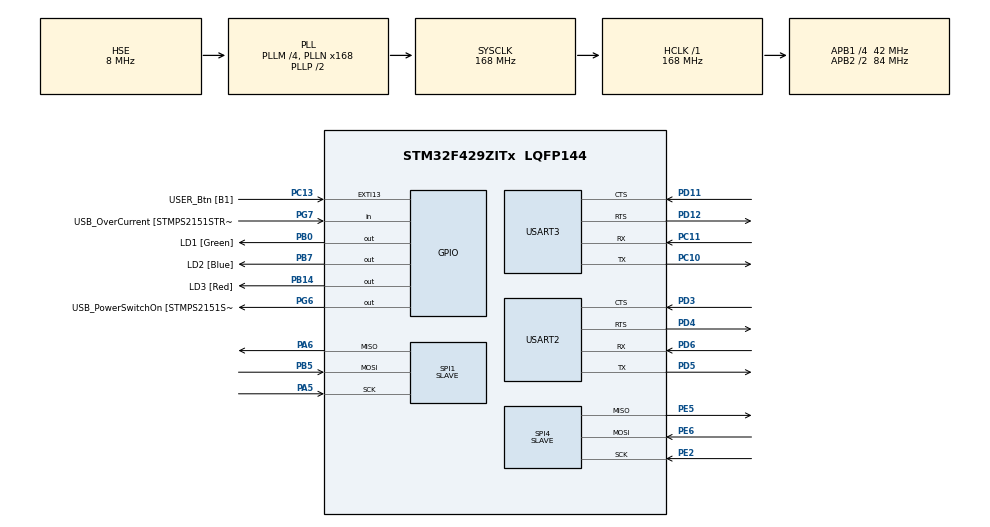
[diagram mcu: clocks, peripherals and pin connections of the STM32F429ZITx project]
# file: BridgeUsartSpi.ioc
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Dma.Request0=USART2_RX
Dma.Request1=SPI4_TX
Dma.Request2=SPI4_RX
Dma.Request3=USART2_TX
Dma.SPI4_RX.2.Direction=DMA_PERIPH_TO_MEMORY
Dma.SPI4_RX.2.FIFOMode=DMA_FIFOMODE_ENABLE
Dma.SPI4_RX.2.FIFOThreshold=DMA_FIFO_THRESHOLD_FULL
Dma.SPI4_RX.2.Instance=DMA2_Stream0
Dma.SPI4_RX.2.MemBurst=DMA_MBURST_SINGLE
Dma.SPI4_RX.2.MemDataAlignment=DMA_MDATAALIGN_BYTE
Dma.SPI4_RX.2.MemInc=DMA_MINC_ENABLE
Dma.SPI4_RX.2.Mode=DMA_CIRCULAR
Dma.SPI4_RX.2.PeriphBurst=DMA_PBURST_SINGLE
Dma.SPI4_RX.2.PeriphDataAlignment=DMA_PDATAALIGN_BYTE
Dma.SPI4_RX.2.PeriphInc=DMA_PINC_DISABLE
Dma.SPI4_RX.2.Priority=DMA_PRIORITY_LOW
Dma.SPI4_TX.1.Direction=DMA_MEMORY_TO_PERIPH
Dma.SPI4_TX.1.FIFOMode=DMA_FIFOMODE_ENABLE
Dma.SPI4_TX.1.FIFOThreshold=DMA_FIFO_THRESHOLD_FULL
Dma.SPI4_TX.1.Instance=DMA2_Stream1
Dma.SPI4_TX.1.MemBurst=DMA_MBURST_SINGLE
Dma.SPI4_TX.1.MemDataAlignment=DMA_MDATAALIGN_BYTE
Dma.SPI4_TX.1.MemInc=DMA_MINC_ENABLE
Dma.SPI4_TX.1.Mode=DMA_CIRCULAR
Dma.SPI4_TX.1.PeriphBurst=DMA_PBURST_SINGLE
Dma.SPI4_TX.1.PeriphDataAlignment=DMA_PDATAALIGN_BYTE
Dma.SPI4_TX.1.PeriphInc=DMA_PINC_DISABLE
Dma.SPI4_TX.1.Priority=DMA_PRIORITY_LOW
Dma.USART2_RX.0.Direction=DMA_PERIPH_TO_MEMORY
Dma.USART2_RX.0.FIFOMode=DMA_FIFOMODE_ENABLE
Dma.USART2_RX.0.FIFOThreshold=DMA_FIFO_THRESHOLD_FULL
Dma.USART2_RX.0.Instance=DMA1_Stream5
Dma.USART2_RX.0.MemBurst=DMA_MBURST_SINGLE
Dma.USART2_RX.0.MemDataAlignment=DMA_MDATAALIGN_BYTE
Dma.USART2_RX.0.MemInc=DMA_MINC_ENABLE
Dma.USART2_RX.0.Mode=DMA_CIRCULAR
Dma.USART2_RX.0.PeriphBurst=DMA_PBURST_SINGLE
Dma.USART2_RX.0.PeriphDataAlignment=DMA_PDATAALIGN_BYTE
Dma.USART2_RX.0.PeriphInc=DMA_PINC_DISABLE
Dma.USART2_RX.0.Priority=DMA_PRIORITY_LOW
Dma.USART2_TX.3.Direction=DMA_MEMORY_TO_PERIPH
Dma.USART2_TX.3.FIFOMode=DMA_FIFOMODE_ENABLE
Dma.USART2_TX.3.FIFOThreshold=DMA_FIFO_THRESHOLD_FULL
Dma.USART2_TX.3.Instance=DMA1_Stream6
Dma.USART2_TX.3.MemBurst=DMA_MBURST_SINGLE
Dma.USART2_TX.3.MemDataAlignment=DMA_MDATAALIGN_BYTE
Dma.USART2_TX.3.MemInc=DMA_MINC_ENABLE
Dma.USART2_TX.3.Mode=DMA_CIRCULAR
Dma.USART2_TX.3.PeriphBurst=DMA_PBURST_SINGLE
Dma.USART2_TX.3.PeriphDataAlignment=DMA_PDATAALIGN_BYTE
Dma.USART2_TX.3.PeriphInc=DMA_PINC_DISABLE
Dma.USART2_TX.3.Priority=DMA_PRIORITY_LOW
FREERTOS.Tasks01=defaultTask,24,128,StartDefaultTask,Default,NULL,Dynamic,NULL,NULL;srvUsart,8,128,StartSrvUsart,Default,NULL,Dynamic,NULL,NULL;srvSpi,8,128,StartSrvSpi,Default,NULL,Dynamic,NULL,NULL;testSenderUsart,8,128,StartSenderUsart,Default,NULL,Dynamic,NULL,NULL;testSenderSpi,8,128,StartSenderSpi,Default,NULL,Dynamic,NULL,NULL
Mcu.Family=STM32F4
Mcu.Name=STM32F429ZITx
Mcu.Package=LQFP144
NVIC.DMA1_Stream5_IRQn=true\:5\:0\:false\:false\:true\:true\:false\:true\:true
NVIC.DMA1_Stream6_IRQn=true\:5\:0\:false\:false\:true\:true\:false\:true\:true
NVIC.DMA2_Stream0_IRQn=true\:5\:0\:false\:false\:true\:true\:false\:true\:true
NVIC.DMA2_Stream1_IRQn=true\:5\:0\:false\:false\:true\:true\:false\:true\:true
NVIC.PriorityGroup=NVIC_PRIORITYGROUP_4
NVIC.TIM8_TRG_COM_TIM14_IRQn=true\:15\:0\:false\:false\:true\:false\:false\:true\:true
NVIC.TimeBase=TIM8_TRG_COM_TIM14_IRQn
NVIC.TimeBaseIP=TIM14
PA13.GPIO_Label=TMS
PA13.Signal=SYS_JTMS-SWDIO
PA5.Mode=Full_Duplex_Slave
PA5.Signal=SPI1_SCK
PA6.Mode=Full_Duplex_Slave
PA6.Signal=SPI1_MISO
PB0.GPIO_Label=LD1 [Green]
PB0.Signal=GPIO_Output
PB14.GPIO_Label=LD3 [Red]
PB14.Signal=GPIO_Output
PB5.Mode=Full_Duplex_Slave
PB5.Signal=SPI1_MOSI
PB7.GPIO_Label=LD2 [Blue]
PB7.Signal=GPIO_Output
PC10.Mode=Asynchronous
PC10.Signal=USART3_TX
PC11.Mode=Asynchronous
PC11.Signal=USART3_RX
PC13.GPIO_Label=USER_Btn [B1]
PC13.Signal=GPXTI13
PC14/OSC32_IN.Mode=LSE-External-Oscillator
PC14/OSC32_IN.Signal=RCC_OSC32_IN
PC15/OSC32_OUT.Mode=LSE-External-Oscillator
PC15/OSC32_OUT.Signal=RCC_OSC32_OUT
PD11.Mode=CTS_RTS
PD11.Signal=USART3_CTS
PD12.Mode=CTS_RTS
PD12.Signal=USART3_RTS
PD3.Mode=CTS_RTS
PD3.Signal=USART2_CTS
PD4.Mode=CTS_RTS
PD4.Signal=USART2_RTS
PD5.Mode=Asynchronous
PD5.Signal=USART2_TX
PD6.Mode=Asynchronous
PD6.Signal=USART2_RX
PE2.Mode=Full_Duplex_Slave
PE2.Signal=SPI4_SCK
PE5.Mode=Full_Duplex_Slave
PE5.Signal=SPI4_MISO
PE6.Mode=Full_Duplex_Slave
PE6.Signal=SPI4_MOSI
PG11.GPIO_Label=RMII_TX_EN [LAN8742A-CZ-TR_TXEN]
PG11.Signal=ETH_TX_EN
PG6.GPIO_Label=USB_PowerSwitchOn [STMPS2151STR_EN]
PG6.Signal=GPIO_Output
PG7.GPIO_Label=USB_OverCurrent [STMPS2151STR_FAULT]
PG7.Signal=GPIO_Input
PH0/OSC_IN.GPIO_Label=MCO [STM32F103CBT6_PA8]
PH0/OSC_IN.Mode=HSE-External-Clock-Source
PH0/OSC_IN.Signal=RCC_OSC_IN
PH1/OSC_OUT.Mode=HSE-External-Clock-Source
PH1/OSC_OUT.Signal=RCC_OSC_OUT
ProjectManager.HeapSize=0x200
ProjectManager.StackSize=0x400
ProjectManager.TargetToolchain=Makefile
RCC.48MHZClocksFreq_Value=48000000
RCC.AHBFreq_Value=168000000
RCC.APB1CLKDivider=RCC_HCLK_DIV4
RCC.APB1Freq_Value=42000000
RCC.APB1TimFreq_Value=84000000
RCC.APB2CLKDivider=RCC_HCLK_DIV2
RCC.APB2Freq_Value=84000000
RCC.APB2TimCLKDivider=2
RCC.APB2TimFreq_Value=168000000
RCC.CortexFreq_Value=168000000
RCC.HCLKFreq_Value=168000000
RCC.HSE_VALUE=8000000
RCC.HSI_VALUE=16000000
RCC.PLLM=4
RCC.PLLMUL=RCC_PLL_MUL9
RCC.PLLN=168
RCC.PLLQ=7
RCC.PLLSourceVirtual=RCC_PLLSOURCE_HSE
RCC.PRESCALERUSB=RCC_USBCLKSOURCE_PLL_DIV1_5
RCC.SYSCLKFreq_VALUE=168000000
RCC.SYSCLKSource=RCC_SYSCLKSOURCE_PLLCLK
RCC.SYSCLKSourceVirtual=RCC_SYSCLKSOURCE_PLLCLK
RCC.USBFreq_Value=48000000
RCC.VCOOutputFreq_Value=336000000
SPI1.Direction=SPI_DIRECTION_2LINES
SPI1.Mode=SPI_MODE_SLAVE
SPI1.VirtualType=VM_SLAVE
SPI4.Direction=SPI_DIRECTION_2LINES
SPI4.Mode=SPI_MODE_SLAVE
SPI4.VirtualType=VM_SLAVE
USART2.VirtualMode=VM_ASYNC
USART3.VirtualMode=VM_ASYNC
VP_FREERTOS_VS_CMSIS_V2.Mode=CMSIS_V2
VP_SYS_VS_tim14.Mode=TIM14
board=NUCLEO-F429ZI

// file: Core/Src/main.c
/* USER CODE BEGIN Header */
/**
  ******************************************************************************
  * @file           : main.c
  * @brief          : Main program body
  ******************************************************************************
  * @attention
  *
  * Copyright (c) 2023 STMicroelectronics.
  * All rights reserved.
  *
  * This software is licensed under terms that can be found in the LICENSE file
  * in the root directory of this software component.
  * If no LICENSE file comes with this software, it is provided AS-IS.
  *
  ******************************************************************************
  */
/* USER CODE END Header */
#include "main.h"
#include "cmsis_os.h"

/* USER CODE BEGIN Includes */
#include "test_sender.h"
/* USER CODE END Includes */

SPI_HandleTypeDef hspi1;
SPI_HandleTypeDef hspi4;
DMA_HandleTypeDef hdma_spi4_tx;
DMA_HandleTypeDef hdma_spi4_rx;

UART_HandleTypeDef huart2;
UART_HandleTypeDef huart3;
DMA_HandleTypeDef hdma_usart2_rx;
DMA_HandleTypeDef hdma_usart2_tx;

/* Definitions for defaultTask */
osThreadId_t defaultTaskHandle;
const osThreadAttr_t defaultTask_attributes = {
  .name = "defaultTask",
  .stack_size = 128 * 4,
  .priority = (osPriority_t) osPriorityNormal,
};
/* Definitions for srvUsart */
osThreadId_t srvUsartHandle;
const osThreadAttr_t srvUsart_attributes = {
  .name = "srvUsart",
  .stack_size = 128 * 4,
  .priority = (osPriority_t) osPriorityLow,
};
/* Definitions for srvSpi */
osThreadId_t srvSpiHandle;
const osThreadAttr_t srvSpi_attributes = {
  .name = "srvSpi",
  .stack_size = 128 * 4,
  .priority = (osPriority_t) osPriorityLow,
};
/* Definitions for testSenderUsart */
osThreadId_t testSenderUsartHandle;
const osThreadAttr_t testSenderUsart_attributes = {
  .name = "testSenderUsart",
  .stack_size = 128 * 4,
  .priority = (osPriority_t) osPriorityLow,
};
/* Definitions for testSenderSpi */
osThreadId_t testSenderSpiHandle;
const osThreadAttr_t testSenderSpi_attributes = {
  .name = "testSenderSpi",
  .stack_size = 128 * 4,
  .priority = (osPriority_t) osPriorityLow,
};

void SystemClock_Config(void);
static void MX_GPIO_Init(void);
static void MX_DMA_Init(void);
static void MX_SPI1_Init(void);
static void MX_SPI4_Init(void);
static void MX_USART2_UART_Init(void);
static void MX_USART3_UART_Init(void);
void StartDefaultTask(void *argument);
void StartSrvUsart(void *argument);
void StartSrvSpi(void *argument);
void StartSenderUsart(void *argument);
void StartSenderSpi(void *argument);

int main(void)
{

  /* MCU Configuration--------------------------------------------------------*/

  /* Reset of all peripherals, Initializes the Flash interface and the Systick. */
  HAL_Init();

  /* Configure the system clock */
  SystemClock_Config();

  /* Initialize all configured peripherals */
  MX_GPIO_Init();
  MX_DMA_Init();
  MX_SPI1_Init();
  MX_SPI4_Init();
  MX_USART2_UART_Init();
  MX_USART3_UART_Init();

  /* Init scheduler */
  osKernelInitialize();

  /* Create the thread(s) */
  /* creation of defaultTask */
  defaultTaskHandle = osThreadNew(StartDefaultTask, NULL, &defaultTask_attributes);

  /* creation of srvUsart */
  srvUsartHandle = osThreadNew(StartSrvUsart, NULL, &srvUsart_attributes);

  /* creation of srvSpi */
  srvSpiHandle = osThreadNew(StartSrvSpi, NULL, &srvSpi_attributes);

  /* creation of testSenderUsart */
  testSenderUsartHandle = osThreadNew(StartSenderUsart, NULL, &testSenderUsart_attributes);

  /* creation of testSenderSpi */
  testSenderSpiHandle = osThreadNew(StartSenderSpi, NULL, &testSenderSpi_attributes);

  /* Start scheduler */
  osKernelStart();

  /* We should never get here as control is now taken by the scheduler */
  /* Infinite loop */
  while (1)
  {

  }
}

void SystemClock_Config(void)
{
  RCC_OscInitTypeDef RCC_OscInitStruct = {0};
  RCC_ClkInitTypeDef RCC_ClkInitStruct = {0};

  /** Configure the main internal regulator output voltage
  */
  __HAL_RCC_PWR_CLK_ENABLE();
  __HAL_PWR_VOLTAGESCALING_CONFIG(PWR_REGULATOR_VOLTAGE_SCALE1);

  /** Initializes the RCC Oscillators according to the specified parameters
  * in the RCC_OscInitTypeDef structure.
  */
  RCC_OscInitStruct.OscillatorType = RCC_OSCILLATORTYPE_HSE;
  RCC_OscInitStruct.HSEState = RCC_HSE_BYPASS;
  RCC_OscInitStruct.PLL.PLLState = RCC_PLL_ON;
  RCC_OscInitStruct.PLL.PLLSource = RCC_PLLSOURCE_HSE;
  RCC_OscInitStruct.PLL.PLLM = 4;
  RCC_OscInitStruct.PLL.PLLN = 168;
  RCC_OscInitStruct.PLL.PLLP = RCC_PLLP_DIV2;
  RCC_OscInitStruct.PLL.PLLQ = 7;
  if (HAL_RCC_OscConfig(&RCC_OscInitStruct) != HAL_OK)
  {
    Error_Handler();
  }

  /** Initializes the CPU, AHB and APB buses clocks
  */
  RCC_ClkInitStruct.ClockType = RCC_CLOCKTYPE_HCLK|RCC_CLOCKTYPE_SYSCLK
                              |RCC_CLOCKTYPE_PCLK1|RCC_CLOCKTYPE_PCLK2;
  RCC_ClkInitStruct.SYSCLKSource = RCC_SYSCLKSOURCE_PLLCLK;
  RCC_ClkInitStruct.AHBCLKDivider = RCC_SYSCLK_DIV1;
  RCC_ClkInitStruct.APB1CLKDivider = RCC_HCLK_DIV4;
  RCC_ClkInitStruct.APB2CLKDivider = RCC_HCLK_DIV2;

  if (HAL_RCC_ClockConfig(&RCC_ClkInitStruct, FLASH_LATENCY_5) != HAL_OK)
  {
    Error_Handler();
  }
}

static void MX_SPI1_Init(void)
{

  /* SPI1 parameter configuration*/
  hspi1.Instance = SPI1;
  hspi1.Init.Mode = SPI_MODE_SLAVE;
  hspi1.Init.Direction = SPI_DIRECTION_2LINES;
  hspi1.Init.DataSize = SPI_DATASIZE_8BIT;
  hspi1.Init.CLKPolarity = SPI_POLARITY_LOW;
  hspi1.Init.CLKPhase = SPI_PHASE_1EDGE;
  hspi1.Init.NSS = SPI_NSS_SOFT;
  hspi1.Init.FirstBit = SPI_FIRSTBIT_MSB;
  hspi1.Init.TIMode = SPI_TIMODE_DISABLE;
  hspi1.Init.CRCCalculation = SPI_CRCCALCULATION_DISABLE;
  hspi1.Init.CRCPolynomial = 10;
  if (HAL_SPI_Init(&hspi1) != HAL_OK)
  {
    Error_Handler();
  }

}

static void MX_SPI4_Init(void)
{

  /* SPI4 parameter configuration*/
  hspi4.Instance = SPI4;
  hspi4.Init.Mode = SPI_MODE_SLAVE;
  hspi4.Init.Direction = SPI_DIRECTION_2LINES;
  hspi4.Init.DataSize = SPI_DATASIZE_8BIT;
  hspi4.Init.CLKPolarity = SPI_POLARITY_LOW;
  hspi4.Init.CLKPhase = SPI_PHASE_1EDGE;
  hspi4.Init.NSS = SPI_NSS_SOFT;
  hspi4.Init.FirstBit = SPI_FIRSTBIT_MSB;
  hspi4.Init.TIMode = SPI_TIMODE_DISABLE;
  hspi4.Init.CRCCalculation = SPI_CRCCALCULATION_DISABLE;
  hspi4.Init.CRCPolynomial = 10;
  if (HAL_SPI_Init(&hspi4) != HAL_OK)
  {
    Error_Handler();
  }

}

static void MX_USART2_UART_Init(void)
{

  huart2.Instance = USART2;
  huart2.Init.BaudRate = 115200;
  huart2.Init.WordLength = UART_WORDLENGTH_8B;
  huart2.Init.StopBits = UART_STOPBITS_1;
  huart2.Init.Parity = UART_PARITY_NONE;
  huart2.Init.Mode = UART_MODE_TX_RX;
  huart2.Init.HwFlowCtl = UART_HWCONTROL_RTS_CTS;
  huart2.Init.OverSampling = UART_OVERSAMPLING_16;
  if (HAL_UART_Init(&huart2) != HAL_OK)
  {
    Error_Handler();
  }

}

static void MX_USART3_UART_Init(void)
{

  huart3.Instance = USART3;
  huart3.Init.BaudRate = 115200;
  huart3.Init.WordLength = UART_WORDLENGTH_8B;
  huart3.Init.StopBits = UART_STOPBITS_1;
  huart3.Init.Parity = UART_PARITY_NONE;
  huart3.Init.Mode = UART_MODE_TX_RX;
  huart3.Init.HwFlowCtl = UART_HWCONTROL_RTS_CTS;
  huart3.Init.OverSampling = UART_OVERSAMPLING_16;
  if (HAL_UART_Init(&huart3) != HAL_OK)
  {
    Error_Handler();
  }

}

static void MX_DMA_Init(void)
{

  /* DMA controller clock enable */
  __HAL_RCC_DMA1_CLK_ENABLE();
  __HAL_RCC_DMA2_CLK_ENABLE();

  /* DMA interrupt init */
  /* DMA1_Stream5_IRQn interrupt configuration */
  HAL_NVIC_SetPriority(DMA1_Stream5_IRQn, 5, 0);
  HAL_NVIC_EnableIRQ(DMA1_Stream5_IRQn);
  /* DMA1_Stream6_IRQn interrupt configuration */
  HAL_NVIC_SetPriority(DMA1_Stream6_IRQn, 5, 0);
  HAL_NVIC_EnableIRQ(DMA1_Stream6_IRQn);
  /* DMA2_Stream0_IRQn interrupt configuration */
  HAL_NVIC_SetPriority(DMA2_Stream0_IRQn, 5, 0);
  HAL_NVIC_EnableIRQ(DMA2_Stream0_IRQn);
  /* DMA2_Stream1_IRQn interrupt configuration */
  HAL_NVIC_SetPriority(DMA2_Stream1_IRQn, 5, 0);
  HAL_NVIC_EnableIRQ(DMA2_Stream1_IRQn);

}

static void MX_GPIO_Init(void)
{
  GPIO_InitTypeDef GPIO_InitStruct = {0};

  /* GPIO Ports Clock Enable */
  __HAL_RCC_GPIOC_CLK_ENABLE();
  __HAL_RCC_GPIOH_CLK_ENABLE();
  __HAL_RCC_GPIOA_CLK_ENABLE();
  __HAL_RCC_GPIOB_CLK_ENABLE();
  __HAL_RCC_GPIOE_CLK_ENABLE();
  __HAL_RCC_GPIOD_CLK_ENABLE();
  __HAL_RCC_GPIOG_CLK_ENABLE();

  /*Configure GPIO pin Output Level */
  HAL_GPIO_WritePin(GPIOB, LD1_Pin|LD3_Pin|LD2_Pin, GPIO_PIN_RESET);

  /*Configure GPIO pin Output Level */
  HAL_GPIO_WritePin(GPIOG, GPIO_PIN_6, GPIO_PIN_RESET);

  /*Configure GPIO pin : USER_Btn_Pin */
  GPIO_InitStruct.Pin = USER_Btn_Pin;
  GPIO_InitStruct.Mode = GPIO_MODE_IT_RISING;
  GPIO_InitStruct.Pull = GPIO_NOPULL;
  HAL_GPIO_Init(USER_Btn_GPIO_Port, &GPIO_InitStruct);

  /*Configure GPIO pins : LD1_Pin LD3_Pin LD2_Pin */
  GPIO_InitStruct.Pin = LD1_Pin|LD3_Pin|LD2_Pin;
  GPIO_InitStruct.Mode = GPIO_MODE_OUTPUT_PP;
  GPIO_InitStruct.Pull = GPIO_NOPULL;
  GPIO_InitStruct.Speed = GPIO_SPEED_FREQ_LOW;
  HAL_GPIO_Init(GPIOB, &GPIO_InitStruct);

  /*Configure GPIO pin : PG6 */
  GPIO_InitStruct.Pin = GPIO_PIN_6;
  GPIO_InitStruct.Mode = GPIO_MODE_OUTPUT_PP;
  GPIO_InitStruct.Pull = GPIO_NOPULL;
  GPIO_InitStruct.Speed = GPIO_SPEED_FREQ_LOW;
  HAL_GPIO_Init(GPIOG, &GPIO_InitStruct);

  /*Configure GPIO pin : USB_OverCurrent_Pin */
  GPIO_InitStruct.Pin = USB_OverCurrent_Pin;
  GPIO_InitStruct.Mode = GPIO_MODE_INPUT;
  GPIO_InitStruct.Pull = GPIO_NOPULL;
  HAL_GPIO_Init(USB_OverCurrent_GPIO_Port, &GPIO_InitStruct);

  /*Configure GPIO pin : RMII_TX_EN_Pin */
  GPIO_InitStruct.Pin = RMII_TX_EN_Pin;
  GPIO_InitStruct.Mode = GPIO_MODE_AF_PP;
  GPIO_InitStruct.Pull = GPIO_NOPULL;
  GPIO_InitStruct.Speed = GPIO_SPEED_FREQ_VERY_HIGH;
  GPIO_InitStruct.Alternate = GPIO_AF11_ETH;
  HAL_GPIO_Init(RMII_TX_EN_GPIO_Port, &GPIO_InitStruct);

}

void StartDefaultTask(void *argument)
{
  for(;;)
  {
    osDelay(1);
  }
}

void StartSrvUsart(void *argument)
{
  /* USER CODE BEGIN StartSrvUsart */
  /* Infinite loop */

  ReceiveUsartMsg(&huart2);
  for(;;)
  {
    ForwardMessagesToSpi(&hspi4);
    osDelay(10);
  }
  /* USER CODE END StartSrvUsart */
}

void StartSrvSpi(void *argument)
{
  /* USER CODE BEGIN StartSrvSpi */
  /* Infinite loop */
    ReceiveSpiMsg(&hspi4);

  for(;;)
  {
    ForwardMessagesToUart(&huart2);
    osDelay(10);
  }
  /* USER CODE END StartSrvSpi */
}

void StartSenderUsart(void *argument)
{
  /* USER CODE BEGIN StartSenderUsart */
  /* Infinite loop */
  for(;;)
  {
    SendUsartMsg(&huart3);
    osDelay(1);
  }
  /* USER CODE END StartSenderUsart */
}

void StartSenderSpi(void *argument)
{
  /* USER CODE BEGIN StartSenderSpi */
  /* Infinite loop */
  for(;;)
  {

    SendSpiMsg(&hspi1);
  }
  /* USER CODE END StartSenderSpi */
}

void HAL_TIM_PeriodElapsedCallback(TIM_HandleTypeDef *htim)
{
  if (htim->Instance == TIM14) {
    HAL_IncTick();
  }
}

void Error_Handler(void)
{
  __disable_irq();
  while (1)
  {
  }
}
